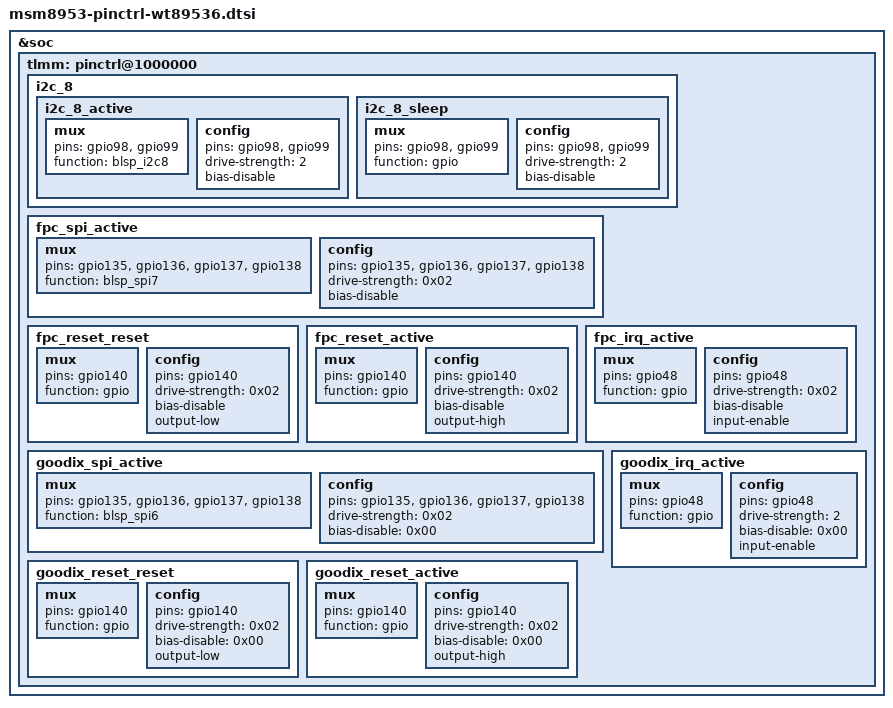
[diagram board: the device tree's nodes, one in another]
/*
 * Copyright (c) 2017, The Linux Foundation. All rights reserved.
 *
 * This program is free software; you can redistribute it and/or modify
 * it under the terms of the GNU General Public License version 2 and
 * only version 2 as published by the Free Software Foundation.
 *
 * This program is distributed in the hope that it will be useful,
 * but WITHOUT ANY WARRANTY; without even the implied warranty of
 * MERCHANTABILITY or FITNESS FOR A PARTICULAR PURPOSE.  See the
 * GNU General Public License for more details.
 */

&soc {
	tlmm: pinctrl@1000000 {
		i2c_8 {
			i2c_8_active: i2c_8_active {
				mux {
					pins = "gpio98", "gpio99";
					function = "blsp_i2c8";
				};

				config {
					pins = "gpio98", "gpio99";
					drive-strength = <2>;
					bias-disable;
				};
			};

			i2c_8_sleep: i2c_8_sleep {
				mux {
					pins = "gpio98", "gpio99";
					function = "gpio";
				};

				config {
					pins = "gpio98", "gpio99";
					drive-strength = <2>;
					bias-disable;
				};
			};
		};

		fpc_spi_active: fpc_spi_active {
			mux {
				pins = "gpio135", "gpio136", "gpio137", "gpio138";
				function = "blsp_spi7";
			};

			config {
				pins = "gpio135", "gpio136", "gpio137", "gpio138";
				drive-strength = <0x02>;
				bias-disable;
			};
		};

		fpc_reset_reset: fpc_reset_reset {
			mux {
				pins = "gpio140";
				function = "gpio";
			};

			config {
				pins = "gpio140";
				drive-strength = <0x02>;
				bias-disable;
				output-low;
			};
		};

		fpc_reset_active: fpc_reset_active {
			mux {
				pins = "gpio140";
				function = "gpio";
			};

			config {
				pins = "gpio140";
				drive-strength = <0x02>;
				bias-disable;
				output-high;
			};
		};

		fpc_irq_active: fpc_irq_active {
			mux {
				pins = "gpio48";
				function = "gpio";
			};

			config {
				pins = "gpio48";
				drive-strength = <0x02>;
				bias-disable;
				input-enable;
			};
		};

		goodix_spi_active: goodix_spi_active {
			mux {
				pins = "gpio135", "gpio136", "gpio137", "gpio138";
				function = "blsp_spi6";
			};

			config {
				pins = "gpio135", "gpio136", "gpio137", "gpio138";
				drive-strength = <0x02>;
				bias-disable = <0x00>;
			};
		};

		goodix_reset_reset: goodix_reset_reset {
			mux {
				pins = "gpio140";
				function = "gpio";
			};

			config {
				pins = "gpio140";
				drive-strength = <0x02>;
				bias-disable = <0x00>;
				output-low;
			};
		};

		goodix_reset_active: goodix_reset_active {
			mux {
				pins = "gpio140";
				function = "gpio";
			};

			config {
				pins = "gpio140";
				drive-strength = <0x02>;
				bias-disable = <0x00>;
				output-high;
			};
		};

		goodix_irq_active: goodix_irq_active {
			mux {
				pins = "gpio48";
				function = "gpio";
			};

			config {
				pins = "gpio48";
				drive-strength = <2>;
				bias-disable = <0x00>;
				input-enable;
			};
		};
	};
};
